# MK20DZ10 register map
Vendor: Freescale Semiconductor, Inc.; Series: Kinetis_K; File version: 1.6
CPU: CM4 r0p1, little endian, no MPU, no FPU, VTOR, 4 interrupt priority bits
Registers are 32-bit, read-write, reset 0x0 unless marked. A register's access mark holds for its fields unless they carry their own. Offsets are from the block's base; [hi:lo] are bit positions; {n}, {i} and the like mark numbered series; 'fields as' and 'values as' point back to an identical list.

## OSC — Oscillator
Base 0x40065000; register names take the prefix OSC_
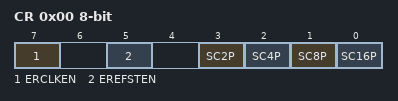
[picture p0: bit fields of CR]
0x00 CR 8-bit — OSC Control Register
  [7] ERCLKEN — External Reference Enable
    0=External reference clock is inactive; 1=External reference clock is enabled
  [5] EREFSTEN — External Reference Stop Enable
    0=External reference clock is disabled in Stop mode; 1=External reference clock stays enabled in Stop mode if ERCLKEN is set before entering Stop mode
  [3] SC2P — Oscillator 2 pF Capacitor Load Configure
    0=Disable the selection; 1=Add 2 pF capacitor to the oscillator load
  [2] SC4P — Oscillator 4 pF Capacitor Load Configure
    0=Disable the selection; 1=Add 4 pF capacitor to the oscillator load
  [1] SC8P — Oscillator 8 pF Capacitor Load Configure
    0=Disable the selection; 1=Add 8 pF capacitor to the oscillator load
  [0] SC16P — Oscillator 16 pF Capacitor Load Configure
    0=Disable the selection; 1=Add 16 pF capacitor to the oscillator load

## VREF — Voltage Reference
Base 0x40074000; register names take the prefix VREF_
0x00 TRM 8-bit reset not defined — VREF Trim Register
  [5:0] TRIM — Trim bits
    0=Min; 63=Max
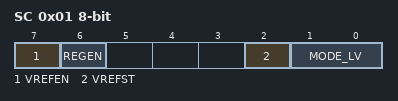
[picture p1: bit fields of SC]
0x01 SC 8-bit — VREF Status and Control Register
  [7] VREFEN — Internal Voltage Reference enable
    0=The module is disabled; 1=The module is enabled
  [6] REGEN — Regulator enable
    0=Internal 1.75 V regulator is disabled; 1=Internal 1.75 V regulator is enabled
  [2] VREFST ro — Internal Voltage Reference has settled
    0=The bandgap is disabled or not ready; 1=The bandgap is ready
  [1:0] MODE_LV — Buffer Mode selection
    0=Bandgap on only, for stabilization and startup; 2=Tight-regulation buffer enabled

## LLWU — Low-leakage wake-up module
Base 0x4007C000; register names take the prefix LLWU_
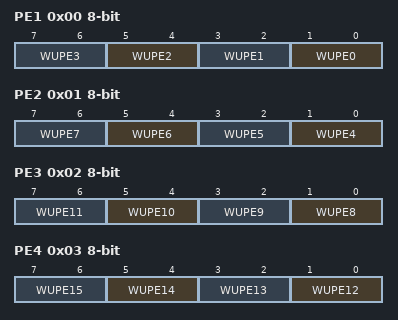
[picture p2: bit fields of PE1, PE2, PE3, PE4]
0x00 PE1 8-bit — LLWU Pin Enable 1 Register
  [all] fields
    0=External input pin disabled as wakeup input; 1=External input pin enabled with rising edge detection; 2=External input pin enabled with falling edge detection; 3=External input pin enabled with any change detection
  [2n+1:2n] WUPE{n} (n=0..3) — Wakeup Pin Enable for LLWU_P{n}
0x01 PE2 8-bit — LLWU Pin Enable 2 Register
  [all] fields
    values as the fields of PE1
  [2n-7:2n-8] WUPE{n} (n=4..7) — Wakeup Pin Enable for LLWU_P{n}
0x02 PE3 8-bit — LLWU Pin Enable 3 Register
  [all] fields
    values as the fields of PE1
  [2n-15:2n-16] WUPE{n} (n=8..11) — Wakeup Pin Enable for LLWU_P{n}
0x03 PE4 8-bit — LLWU Pin Enable 4 Register
  [all] fields
    values as the fields of PE1
  [2n-23:2n-24] WUPE{n} (n=12..15) — Wakeup Pin Enable for LLWU_P{n}
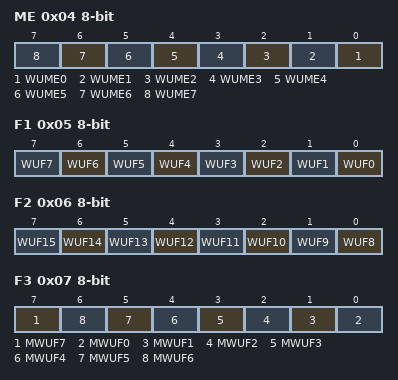
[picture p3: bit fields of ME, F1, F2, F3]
0x04 ME 8-bit — LLWU Module Enable Register
  [all] fields
    0=Internal module flag not used as wakeup source; 1=Internal module flag used as wakeup source
  [n] WUME{n} (n=0..7) — Wakeup Module Enable for Module {n}
0x05 F1 8-bit — LLWU Flag 1 Register
  [n] WUF{n} (n=0..7) — Wakeup Flag for LLWU_P{n}
    0=LLWU_P{n} input was not a source of wakeup from LLS or VLLS mode; 1=LLWU_P{n} input was a source of wakeup from LLS or VLLS mode
0x06 F2 8-bit — LLWU Flag 2 Register
  [n-8] WUF{n} (n=8..15) — Wakeup Flag for LLWU_P{n}
    values as F1.WUF0
0x07 F3 8-bit — LLWU Flag 3 Register
  [7] MWUF7 — Wakeup flag for module 7 (Error Detect)
    0=Module 7 (Error Detect) input was not a source of wakeup from LLS or VLLS mode; 1=Module 7 (Error Detect) input was a source of wakeup from LLS or VLLS mode
  [n] MWUF{n} ro (n=0..6) — Wakeup flag for module {n}
    0=Module {n} input was not a source of wakeup from LLS or VLLS mode; 1=Module {n} input was a source of wakeup from LLS or VLLS mode
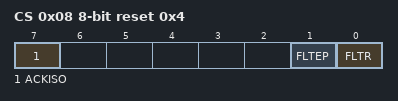
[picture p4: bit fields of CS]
0x08 CS 8-bit reset 0x4 — LLWU Control and Status Register
  [7] ACKISO — Acknowledge Isolation
    0=Peripherals and I/O pads are in normal run state; 1=Certain peripherals and I/O pads are in an isolated and latched state
  [1] FLTEP — Digital Filter on External Pin
    0=Filter not enabled; 1=Filter enabled
  [0] FLTR — Digital Filter on RESET Pin
    0=Filter not enabled; 1=Filter enabled

## Notices in the file
Redistribution and use in source and binary forms, with or without modification,
are permitted provided that the following conditions are met:
o Redistributions of source code must retain the above copyright notice, this list
of conditions and the following disclaimer.
o Redistributions in binary form must reproduce the above copyright notice, this
list of conditions and the following disclaimer in the documentation and/or
other materials provided with the distribution.
o Neither the name of Freescale Semiconductor, Inc. nor the names of its
contributors may be used to endorse or promote products derived from this
software without specific prior written permission.
THIS SOFTWARE IS PROVIDED BY THE COPYRIGHT HOLDERS AND CONTRIBUTORS "AS IS" AND
ANY EXPRESS OR IMPLIED WARRANTIES, INCLUDING, BUT NOT LIMITED TO, THE IMPLIED
WARRANTIES OF MERCHANTABILITY AND FITNESS FOR A PARTICULAR PURPOSE ARE
DISCLAIMED. IN NO EVENT SHALL THE COPYRIGHT HOLDER OR CONTRIBUTORS BE LIABLE FOR
ANY DIRECT, INDIRECT, INCIDENTAL, SPECIAL, EXEMPLARY, OR CONSEQUENTIAL DAMAGES
(INCLUDING, BUT NOT LIMITED TO, PROCUREMENT OF SUBSTITUTE GOODS OR SERVICES;
LOSS OF USE, DATA, OR PROFITS; OR BUSINESS INTERRUPTION) HOWEVER CAUSED AND ON
ANY THEORY OF LIABILITY, WHETHER IN CONTRACT, STRICT LIABILITY, OR TORT
(INCLUDING NEGLIGENCE OR OTHERWISE) ARISING IN ANY WAY OUT OF THE USE OF THIS
SOFTWARE, EVEN IF ADVISED OF THE POSSIBILITY OF SUCH DAMAGE.
